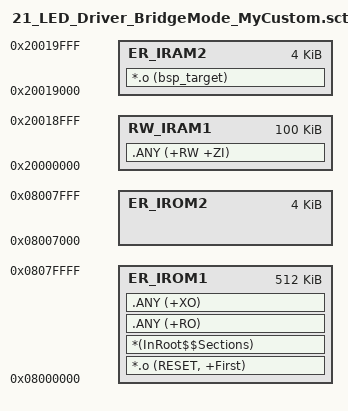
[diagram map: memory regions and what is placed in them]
; *************************************************************
; *** Scatter-Loading Description File generated by uVision ***
; *************************************************************

LR_IROM1 0x08000000 0x00080000  {    ; load region size_region
  ER_IROM1 0x08000000 0x00080000  {  ; load address = execution address
   *.o (RESET, +First)
   *(InRoot$$Sections)
   .ANY (+RO)
   .ANY (+XO)
  }
  RW_IRAM1 0x20000000 0x00019000  {  ; RW data
   .ANY (+RW +ZI)
  }
}

LR_IROM2 0x08007000 0x00001000
{
    ER_IROM2 0x08007000 0x0001000 {

    }
}

LR_IRAM2 0x08007000 0x00001000 {
    ER_IRAM2 0x20019000 0x0001000 {
        *.o (bsp_target)
    }
}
